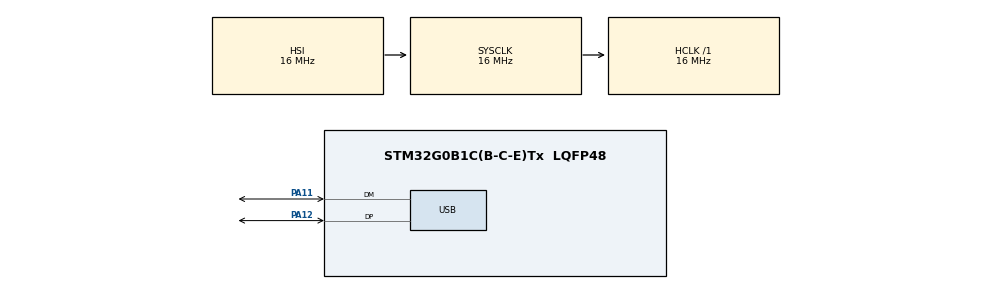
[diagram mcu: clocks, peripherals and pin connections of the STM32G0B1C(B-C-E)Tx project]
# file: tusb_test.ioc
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FREERTOS.Tasks01=defaultTask,24,128,StartDefaultTask,Default,NULL,Dynamic,NULL,NULL;tinyusb,52,512,tinyusb_s,Default,NULL,Dynamic,NULL,NULL
Mcu.Family=STM32G0
Mcu.Name=STM32G0B1C(B-C-E)Tx
Mcu.Package=LQFP48
NVIC.TIM1_BRK_UP_TRG_COM_IRQn=true\:3\:0\:false\:false\:true\:false\:false\:true\:true
NVIC.TimeBase=TIM1_BRK_UP_TRG_COM_IRQn
NVIC.TimeBaseIP=TIM1
NVIC.USB_UCPD1_2_IRQn=true\:3\:0\:false\:false\:true\:true\:true\:true\:true
PA11\ [PA9].Mode=Device
PA11\ [PA9].Signal=USB_DM
PA12\ [PA10].Mode=Device
PA12\ [PA10].Signal=USB_DP
PA13.Mode=Serial_Wire
PA13.Signal=SYS_SWDIO
PA14-BOOT0.Mode=Serial_Wire
PA14-BOOT0.Signal=SYS_SWCLK
ProjectManager.HeapSize=0x200
ProjectManager.StackSize=0x400
ProjectManager.TargetToolchain=CMake
RCC.AHBFreq_Value=16000000
RCC.CortexFreq_Value=16000000
RCC.EXTERNAL_CLOCK_VALUE=48000
RCC.HCLKFreq_Value=16000000
RCC.HSE_VALUE=8000000
RCC.HSI48_VALUE=48000000
RCC.HSI_VALUE=16000000
RCC.LSE_VALUE=32768
RCC.SYSCLKFreq_VALUE=16000000
RCC.USBFreq_Value=48000000
RCC.VCOOutputFreq_Value=128000000
VP_FREERTOS_VS_CMSIS_V2.Mode=CMSIS_V2
VP_SYS_VS_DBSignals.Mode=DisableDeadBatterySignals
VP_SYS_VS_tim1.Mode=TIM1
board=custom

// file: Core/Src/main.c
/* USER CODE BEGIN Header */
/**
  ******************************************************************************
  * @file           : main.c
  * @brief          : Main program body
  ******************************************************************************
  * @attention
  *
  * Copyright (c) 2024 STMicroelectronics.
  * All rights reserved.
  *
  * This software is licensed under terms that can be found in the LICENSE file
  * in the root directory of this software component.
  * If no LICENSE file comes with this software, it is provided AS-IS.
  *
  ******************************************************************************
  */
/* USER CODE END Header */
#include "main.h"
#include "cmsis_os.h"
#include "usb_drd_fs.h"
#include "gpio.h"

void SystemClock_Config(void);
void MX_FREERTOS_Init(void);

int main(void)
{

  /* MCU Configuration--------------------------------------------------------*/

  /* Reset of all peripherals, Initializes the Flash interface and the Systick. */
  HAL_Init();

  /* Configure the system clock */
  SystemClock_Config();

  /* Initialize all configured peripherals */
  MX_GPIO_Init();
  MX_USB_DRD_FS_PCD_Init();

  /* Init scheduler */
  osKernelInitialize();

  /* Call init function for freertos objects (in cmsis_os2.c) */
  MX_FREERTOS_Init();

  /* Start scheduler */
  osKernelStart();

  /* We should never get here as control is now taken by the scheduler */

  /* Infinite loop */
  while (1)
  {

  }
}

void SystemClock_Config(void)
{
  RCC_OscInitTypeDef RCC_OscInitStruct = {0};
  RCC_ClkInitTypeDef RCC_ClkInitStruct = {0};

  /** Configure the main internal regulator output voltage
  */
  HAL_PWREx_ControlVoltageScaling(PWR_REGULATOR_VOLTAGE_SCALE1);

  /** Initializes the RCC Oscillators according to the specified parameters
  * in the RCC_OscInitTypeDef structure.
  */
  RCC_OscInitStruct.OscillatorType = RCC_OSCILLATORTYPE_HSI|RCC_OSCILLATORTYPE_HSI48;
  RCC_OscInitStruct.HSIState = RCC_HSI_ON;
  RCC_OscInitStruct.HSI48State = RCC_HSI48_ON;
  RCC_OscInitStruct.HSIDiv = RCC_HSI_DIV1;
  RCC_OscInitStruct.HSICalibrationValue = RCC_HSICALIBRATION_DEFAULT;
  RCC_OscInitStruct.PLL.PLLState = RCC_PLL_NONE;
  if (HAL_RCC_OscConfig(&RCC_OscInitStruct) != HAL_OK)
  {
    Error_Handler();
  }

  /** Initializes the CPU, AHB and APB buses clocks
  */
  RCC_ClkInitStruct.ClockType = RCC_CLOCKTYPE_HCLK|RCC_CLOCKTYPE_SYSCLK
                              |RCC_CLOCKTYPE_PCLK1;
  RCC_ClkInitStruct.SYSCLKSource = RCC_SYSCLKSOURCE_HSI;
  RCC_ClkInitStruct.AHBCLKDivider = RCC_SYSCLK_DIV1;
  RCC_ClkInitStruct.APB1CLKDivider = RCC_HCLK_DIV1;

  if (HAL_RCC_ClockConfig(&RCC_ClkInitStruct, FLASH_LATENCY_0) != HAL_OK)
  {
    Error_Handler();
  }
}

void HAL_TIM_PeriodElapsedCallback(TIM_HandleTypeDef *htim)
{
  if (htim->Instance == TIM1) {
    HAL_IncTick();
  }
}

void Error_Handler(void)
{
  __disable_irq();
  while (1)
  {
  }
}

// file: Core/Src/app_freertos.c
/* USER CODE BEGIN Header */
/**
  ******************************************************************************
  * File Name          : app_freertos.c
  * Description        : Code for freertos applications
  ******************************************************************************
  * @attention
  *
  * Copyright (c) 2024 STMicroelectronics.
  * All rights reserved.
  *
  * This software is licensed under terms that can be found in the LICENSE file
  * in the root directory of this software component.
  * If no LICENSE file comes with this software, it is provided AS-IS.
  *
  ******************************************************************************
  */
/* USER CODE END Header */

#include "FreeRTOS.h"
#include "cmsis_os.h"
#include "main.h"
#include "task.h"
#include "tusb.h"

/* Definitions for defaultTask */
osThreadId_t defaultTaskHandle;
const osThreadAttr_t defaultTask_attributes = {
  .name = "defaultTask",
  .priority = (osPriority_t) osPriorityNormal,
  .stack_size = 128 * 4
};
/* Definitions for tinyusb */
osThreadId_t tinyusbHandle;
const osThreadAttr_t tinyusb_attributes = {
  .name = "tinyusb",
  .priority = (osPriority_t) osPriorityRealtime4,
  .stack_size = 512 * 4
};

void StartDefaultTask(void *argument);
void tinyusb_s(void *argument);

void MX_FREERTOS_Init(void); /* (MISRA C 2004 rule 8.1) */

void MX_FREERTOS_Init(void) {

  /* Create the thread(s) */
  /* creation of defaultTask */
  defaultTaskHandle = osThreadNew(StartDefaultTask, NULL, &defaultTask_attributes);

  /* creation of tinyusb */
  tinyusbHandle = osThreadNew(tinyusb_s, NULL, &tinyusb_attributes);

}

void StartDefaultTask(void *argument)
{
  for(;;)
  {
    osDelay(1);
  }
}

void tinyusb_s(void *argument)
{
  /* USER CODE BEGIN tinyusb_s */
  tusb_init();
  /* Infinite loop */
  for(;;)
  {
    tud_task();
    tud_cdc_write_flush();
    taskYIELD();
  }
  /* USER CODE END tinyusb_s */
}
